# FM33FK5XX register map
File version: 1.0
CPU: Cortex-M33 r1p0, little endian, MPU, FPU, 3 interrupt priority bits
Registers are 32-bit, read-write, reset 0x0 unless marked. A register's access mark holds for its fields unless they carry their own. Offsets are from the block's base; [hi:lo] are bit positions; {n}, {i} and the like mark numbered series.

## ATIM0 — ATIM0 module information
Base 0x40018400
Same registers: ATIM1 0x4001B000
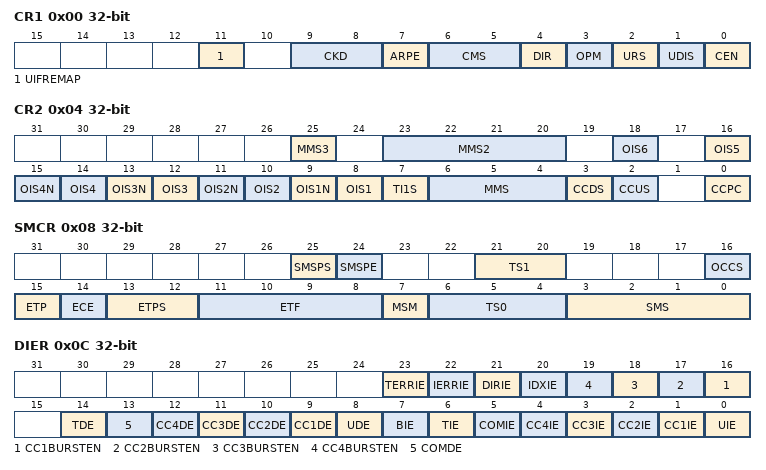
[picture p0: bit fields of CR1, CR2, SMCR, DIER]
0x00 CR1
  [11] UIFREMAP — UIFREMAP field description
  [9:8] CKD — CKD field description
  [7] ARPE — ARPE field description
  [6:5] CMS — CMS field description
  [4] DIR — DIR field description
  [3] OPM — OPM field description
  [2] URS — URS field description
  [1] UDIS — UDIS field description
  [0] CEN — CEN field description
0x04 CR2
  [25] MMS3 — MMS3 field description
  [23:20] MMS2 — MMS2 field description
  [2n+6] OIS{n} (n=1..6) — OIS{n} field description
  [2n+7] OIS{n}N (n=1..4) — OIS{n}N field description
  [7] TI1S — TI1S field description
  [6:4] MMS — MMS field description
  [3] CCDS — CCDS field description
  [2] CCUS — CCUS field description
  [0] CCPC — CCPC field description
0x08 SMCR
  [25] SMSPS — SMSPS field description
  [24] SMSPE — SMSPE field description
  [21:20] TS1 — TS1 field description
  [16] OCCS — OCCS field description
  [15] ETP — ETP field description
  [14] ECE — ECE field description
  [13:12] ETPS — ETPS field description
  [11:8] ETF — ETF field description
  [7] MSM — MSM field description
  [6:4] TS0 — TS0 field description
  [3:0] SMS — SMS field description
0x0C DIER
  [23] TERRIE — TERRIE field description
  [22] IERRIE — IERRIE field description
  [21] DIRIE — DIRIE field description
  [20] IDXIE — IDXIE field description
  [n+15] CC{n}BURSTEN (n=1..4) — CC{n}BURSTEN field description
  [14] TDE — TDE field description
  [13] COMDE — COMDE field description
  [n+8] CC{n}DE (n=1..4) — CC{n}DE field description
  [8] UDE — UDE field description
  [7] BIE — BIE field description
  [6] TIE — TIE field description
  [5] COMIE — COMIE field description
  [n] CC{n}IE (n=1..4) — CC{n}IE field description
  [0] UIE — UIE field description
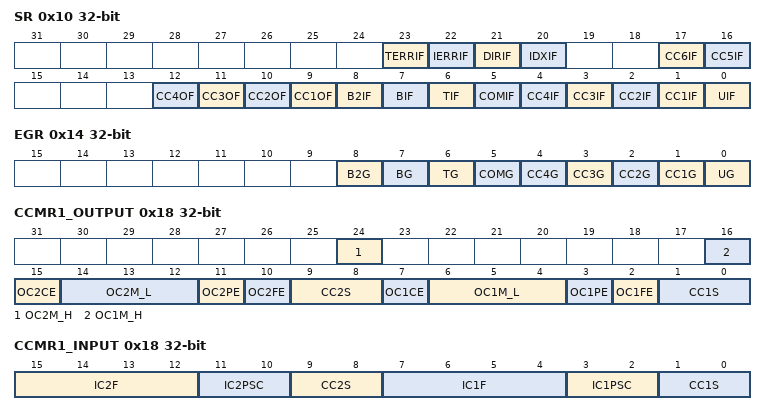
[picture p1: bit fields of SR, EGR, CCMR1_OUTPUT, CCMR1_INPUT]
0x10 SR
  [23] TERRIF — TERRIF field description
  [22] IERRIF — IERRIF field description
  [21] DIRIF — DIRIF field description
  [20] IDXIF — IDXIF field description
  [17] CC6IF — CC6IF field description
  [16] CC5IF — CC5IF field description
  [n+8] CC{n}OF (n=1..4) — CC{n}OF field description
  [8] B2IF — B2IF field description
  [7] BIF — BIF field description
  [6] TIF — TIF field description
  [5] COMIF — COMIF field description
  [n] CC{n}IF (n=1..4) — CC{n}IF field description
  [0] UIF — UIF field description
0x14 EGR wo
  [8] B2G — B2G field description
  [7] BG — BG field description
  [6] TG — TG field description
  [5] COMG — COMG field description
  [n] CC{n}G (n=1..4) — CC{n}G field description
  [0] UG — UG field description
0x18 CCMR1_OUTPUT
  [24] OC2M_H — OC2M_H field description
  [16] OC1M_H — OC1M_H field description
  [15] OC2CE — OC2CE field description
  [14:12] OC2M_L — OC2M_L field description
  [11] OC2PE — OC2PE field description
  [10] OC2FE — OC2FE field description
  [9:8] CC2S — CC2S field description
  [7] OC1CE — OC1CE field description
  [6:4] OC1M_L — OC1M_L field description
  [3] OC1PE — OC1PE field description
  [2] OC1FE — OC1FE field description
  [1:0] CC1S — CC1S field description
0x18 CCMR1_INPUT (alternate view of CCMR1_OUTPUT)
  [15:12] IC2F — IC2F field description
  [11:10] IC2PSC — IC2PSC field description
  [9:8] CC2S — CC2S field description
  [7:4] IC1F — IC1F field description
  [3:2] IC1PSC — IC1PSC field description
  [1:0] CC1S — CC1S field description
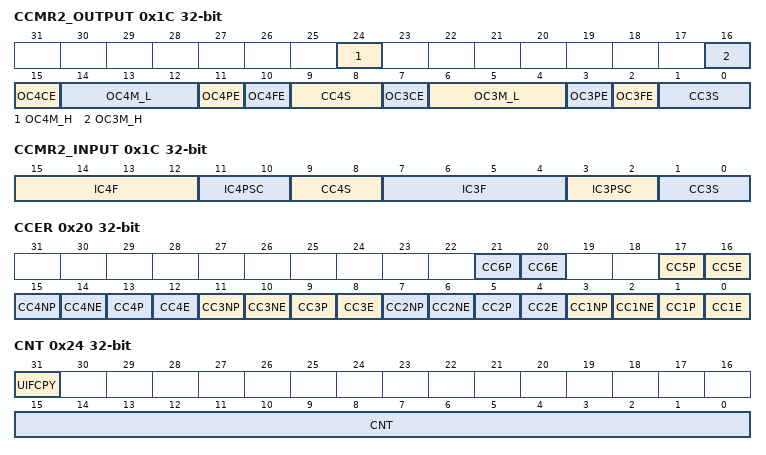
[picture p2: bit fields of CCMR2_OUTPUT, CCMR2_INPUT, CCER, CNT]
0x1C CCMR2_OUTPUT
  [24] OC4M_H — OC4M_H field description
  [16] OC3M_H — OC3M_H field description
  [15] OC4CE — OC4CE field description
  [14:12] OC4M_L — OC4M_L field description
  [11] OC4PE — OC4PE field description
  [10] OC4FE — OC4FE field description
  [9:8] CC4S — CC4S field description
  [7] OC3CE — OC3CE field description
  [6:4] OC3M_L — OC3M_L field description
  [3] OC3PE — OC3PE field description
  [2] OC3FE — OC3FE field description
  [1:0] CC3S — CC3S field description
0x1C CCMR2_INPUT (alternate view of CCMR2_OUTPUT)
  [15:12] IC4F — IC4F field description
  [11:10] IC4PSC — IC4PSC field description
  [9:8] CC4S — CC4S field description
  [7:4] IC3F — IC3F field description
  [3:2] IC3PSC — IC3PSC field description
  [1:0] CC3S — CC3S field description
0x20 CCER
  [4n-3] CC{n}P (n=1..6) — CC{n}P field description
  [4n-4] CC{n}E (n=1..6) — CC{n}E field description
  [4n-1] CC{n}NP (n=1..4) — CC{n}NP field description
  [4n-2] CC{n}NE (n=1..4) — CC{n}NE field description
0x24 CNT access per field
  [31] UIFCPY ro — UIFCPY field description
  [15:0] CNT rw — CNT field description
0x28 PSC
  [15:0] PSC — PSC field description
0x2C ARR reset 0xFFFF
  [15:0] ARR — ARR field description
0x30 RCR
  [7:0] REP — REP field description
{0x30+4i} CCR{i} (i=1..4)
  [15:0] CCR{i} — CCR{i} field description
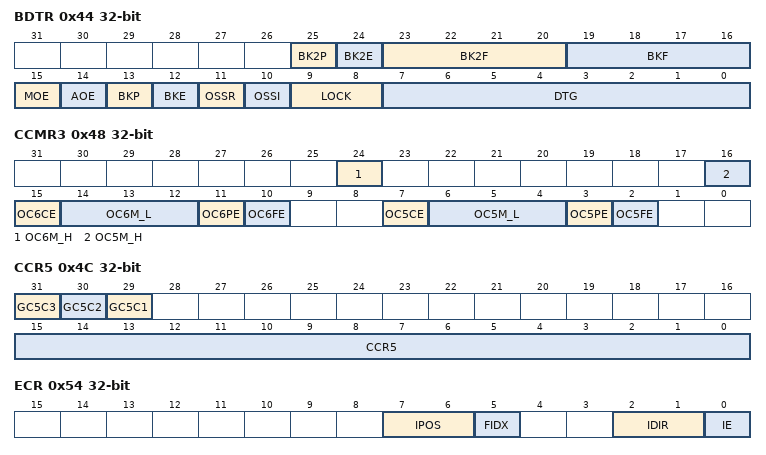
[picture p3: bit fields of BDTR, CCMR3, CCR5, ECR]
0x44 BDTR
  [25] BK2P — BK2P field description
  [24] BK2E — BK2E field description
  [23:20] BK2F — BK2F field description
  [19:16] BKF — BKF field description
  [15] MOE — MOE field description
  [14] AOE — AOE field description
  [13] BKP — BKP field description
  [12] BKE — BKE field description
  [11] OSSR — OSSR field description
  [10] OSSI — OSSI field description
  [9:8] LOCK — LOCK field description
  [7:0] DTG — DTG field description
0x48 CCMR3
  [24] OC6M_H — OC6M_H field description
  [16] OC5M_H — OC5M_H field description
  [15] OC6CE — OC6CE field description
  [14:12] OC6M_L — OC6M_L field description
  [11] OC6PE — OC6PE field description
  [10] OC6FE — OC6FE field description
  [7] OC5CE — OC5CE field description
  [6:4] OC5M_L — OC5M_L field description
  [3] OC5PE — OC5PE field description
  [2] OC5FE — OC5FE field description
0x4C CCR5
  [31] GC5C3 — GC5C3 field description
  [30] GC5C2 — GC5C2 field description
  [29] GC5C1 — GC5C1 field description
  [15:0] CCR5 — CCR5 field description
0x50 CCR6
  [15:0] CCR6 — CCR6 field description
0x54 ECR
  [7:6] IPOS — IPOS field description
  [5] FIDX — FIDX field description
  [2:1] IDIR — IDIR field description
  [0] IE — IE field description
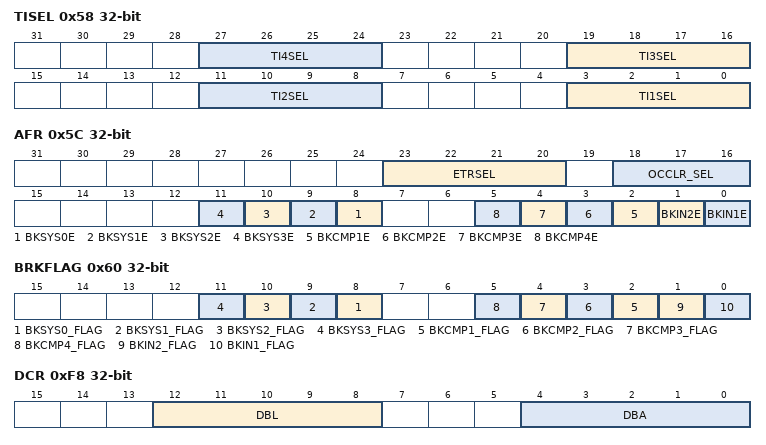
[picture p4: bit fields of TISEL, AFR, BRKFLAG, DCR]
0x58 TISEL
  [8n-5:8n-8] TI{n}SEL (n=1..4) — TI{n}SEL field description
0x5C AFR
  [23:20] ETRSEL — ETRSEL field description
  [18:16] OCCLR_SEL — OCCLR_SEL field description
  [n+8] BKSYS{n}E (n=0..3) — BKSYS{n}E field description
  [n+1] BKCMP{n}E (n=1..4) — BKCMP{n}E field description
  [1] BKIN2E — BKIN2E field description
  [0] BKIN1E — BKIN1E field description
0x60 BRKFLAG
  [n+8] BKSYS{n}_FLAG (n=0..3) — BKSYS{n}_FLAG field description
  [n+1] BKCMP{n}_FLAG (n=1..4) — BKCMP{n}_FLAG field description
  [1] BKIN2_FLAG — BKIN2_FLAG field description
  [0] BKIN1_FLAG — BKIN1_FLAG field description
0xF8 DCR
  [12:8] DBL — DBL field description
  [4:0] DBA — DBA field description
0xFC DMAR
  [31:0] DMAR — DMAR field description
